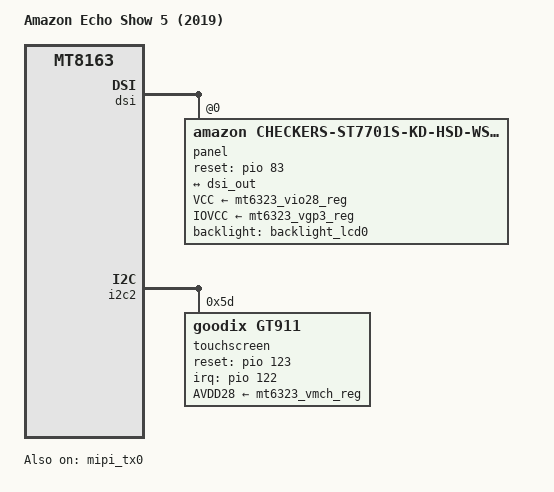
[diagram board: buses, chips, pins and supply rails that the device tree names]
// SPDX-License-Identifier: GPL-2.0-only OR MIT
/*
 * Copyright (c) 2025-2026 Ben Grisdale <bengris32@protonmail.ch>
 * Copyright (c) 2025-2026 Jack Matthews <jack@jackmatthe.ws>
 */

/dts-v1/;

#include "mt8163-amazon-show.dtsi"

/ {
	model = "Amazon Echo Show 5 (2019)";
	compatible = "amazon,checkers", "mediatek,mt8163";
	chassis-type = "embedded";
};

&dsi {
	status = "okay";

	panel: panel@0 {
		compatible = "amazon,checkers-st7701s-kd-hsd-wsvga";
		reg = <0>;
		reset-gpios = <&pio 83 GPIO_ACTIVE_HIGH>;
		backlight = <&backlight_lcd0>;
		VCC-supply = <&mt6323_vio28_reg>;
		IOVCC-supply = <&mt6323_vgp3_reg>;
		rot = <1>;

		port {
			panel_in: endpoint {
				remote-endpoint = <&dsi_out>;
			};
		};
	};
};

&dsi_out {
	remote-endpoint = <&panel_in>;
};

&i2c2 {
	status = "okay";

	touchscreen@5d {
		compatible = "goodix,gt911";
		reg = <0x5d>;
		reset-gpios = <&pio 123 GPIO_ACTIVE_HIGH>;
		irq-gpios = <&pio 122 GPIO_ACTIVE_HIGH>;
		AVDD28-supply = <&mt6323_vmch_reg>;
		touchscreen-size-x = <480>;
		touchscreen-size-y = <960>;

		/* KD */
		goodix,cfg-group0 = [
			56 e0 01 c0 03 05 35 08 01 08 23 05
			5a 32 2f 03 00 00 00 00 22 02 30 14
			1b 1f 14 8c ec 0c 50 52 7c 06 46 41
			61 bb 02 10 00 00 00 00 00 00 00 00
			00 00 00 3c 58 8f e0 65 14 0a 00 04
			9a 3e 00 91 43 00 8a 48 00 82 4e 00
			7b 54 00 7b 00 00 00 00 01 1e 14 00
			00 00 00 50 7c 06 1e 00 18 00 00 00
			00 00 00 00 00 00 00 00 00 00 00 00
			00 00 00 00 18 16 14 12 10 0e 0c 0a
			08 06 04 02 ff ff ff ff ff ff ff ff
			ff ff ff ff ff ff ff ff ff ff 00 02
			04 06 08 0a 0c 0f 10 12 13 14 16 18
			1c 1d 1e 1f 20 21 22 24 26 28 ff ff
			ff ff ff ff ff ff ff ff ff ff ff ff
			ff ff ff ff f2 01];

		/* TRULY */
		goodix,cfg-group1 = [
			56 e0 01 c0 03 05 35 08 01 08 23 05
			5a 32 2f 03 00 00 00 00 22 02 30 14
			1b 1f 14 8c ec 0c 50 52 7c 06 46 41
			61 bb 02 10 00 00 00 00 00 00 00 00
			00 00 00 3c 58 8f e0 65 14 0a 00 04
			9a 3e 00 91 43 00 8a 48 00 82 4e 00
			7b 54 00 7b 00 00 00 00 01 1e 14 00
			00 00 00 50 7c 06 1e 00 18 00 00 00
			00 00 00 00 00 00 00 00 00 00 00 00
			00 00 00 00 18 16 14 12 10 0e 0c 0a
			08 06 04 02 ff ff ff ff ff ff ff ff
			ff ff ff ff ff ff ff ff ff ff 00 02
			04 06 08 0a 0c 0f 10 12 13 14 16 18
			1c 1d 1e 1f 20 21 22 24 26 28 ff ff
			ff ff ff ff ff ff ff ff ff ff ff ff
			ff ff ff ff f2 01];

		/* INX */
		goodix,cfg-group2 = [
			56 e0 01 c0 03 05 35 08 01 08 23 05
			5a 32 2f 03 00 00 00 00 22 02 30 14
			1b 1f 14 8c ec 0c 50 52 7c 06 46 41
			61 bb 02 10 00 00 00 00 00 00 00 00
			00 00 00 3c 58 8f e0 65 14 0a 00 04
			9a 3e 00 91 43 00 8a 48 00 82 4e 00
			7b 54 00 7b 00 00 00 00 01 1e 14 00
			00 00 00 50 7c 06 1e 00 18 00 00 00
			00 00 00 00 00 00 00 00 00 00 00 00
			00 00 00 00 18 16 14 12 10 0e 0c 0a
			08 06 04 02 ff ff ff ff ff ff ff ff
			ff ff ff ff ff ff ff ff ff ff 00 02
			04 06 08 0a 0c 0f 10 13 12 14 16 18
			1c 1d 1e 1f 20 26 28 21 22 24 ff ff
			ff ff ff ff ff ff ff ff ff ff ff ff
			ff ff ff ff f2 01];

		/* KD_WALLY */
		goodix,cfg-group3 = [
			56 e0 01 c0 03 05 35 08 01 08 23 05
			5a 32 2f 03 00 00 00 00 22 02 30 14
			1b 1f 14 8c ec 0c 50 52 7c 06 46 41
			61 bb 02 10 00 00 00 00 00 00 00 00
			00 00 00 3c 58 8f e0 65 14 0a 00 04
			9a 3e 00 91 43 00 8a 48 00 82 4e 00
			7b 54 00 7b 00 00 00 00 01 1e 14 00
			00 00 00 50 7c 06 1e 00 18 00 00 00
			00 00 00 00 00 00 00 00 00 00 00 00
			00 00 00 00 18 16 14 12 10 0e 0c 0a
			08 06 04 02 ff ff ff ff ff ff ff ff
			ff ff ff ff ff ff ff ff ff ff 00 02
			04 06 08 0a 0c 0f 10 12 13 14 16 18
			1c 1d 1e 1f 20 21 22 24 26 28 ff ff
			ff ff ff ff ff ff ff ff ff ff ff ff
			ff ff ff ff f2 01];
	};
};

&mipi_tx0 {
	status = "okay";
};
